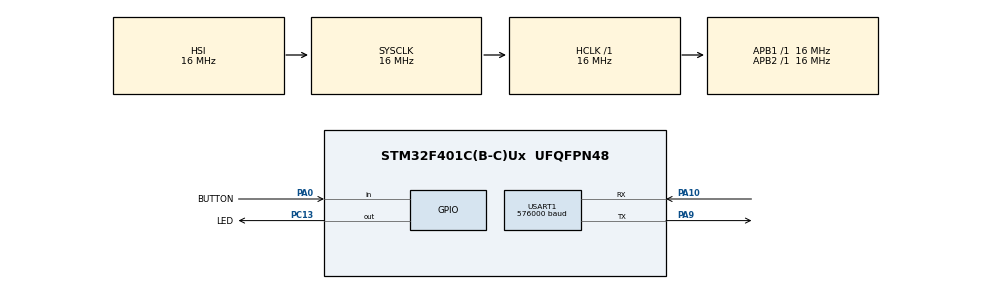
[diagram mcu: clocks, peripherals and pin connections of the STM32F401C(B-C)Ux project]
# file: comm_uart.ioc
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FREERTOS.Queues01=myQueue01,16,uint16_t,0,Static,myQueue01Buffer,myQueue01ControlBlock
FREERTOS.Tasks01=defaultTask,24,128,StartDefaultTask,Default,NULL,Dynamic,NULL,NULL
FREERTOS.configENABLE_FPU=1
FREERTOS.configUSE_NEWLIB_REENTRANT=1
Mcu.Family=STM32F4
Mcu.Name=STM32F401C(B-C)Ux
Mcu.Package=UFQFPN48
NVIC.PriorityGroup=NVIC_PRIORITYGROUP_4
NVIC.TIM5_IRQn=true\:15\:0\:false\:false\:true\:false\:false\:true\:true
NVIC.TimeBase=TIM5_IRQn
NVIC.TimeBaseIP=TIM5
NVIC.USART1_IRQn=true\:5\:0\:false\:false\:true\:true\:true\:true\:true
PA0-WKUP.GPIO_Label=BUTTON
PA0-WKUP.GPIO_PuPd=GPIO_PULLUP
PA0-WKUP.Signal=GPIO_Input
PA10.Mode=Asynchronous
PA10.Signal=USART1_RX
PA13.Mode=Serial_Wire
PA13.Signal=SYS_JTMS-SWDIO
PA14.Mode=Serial_Wire
PA14.Signal=SYS_JTCK-SWCLK
PA9.Mode=Asynchronous
PA9.Signal=USART1_TX
PC13-ANTI_TAMP.GPIO_Label=LED
PC13-ANTI_TAMP.Signal=GPIO_Output
PH0\ -\ OSC_IN.Mode=HSE-External-Oscillator
PH0\ -\ OSC_IN.Signal=RCC_OSC_IN
PH1\ -\ OSC_OUT.Mode=HSE-External-Oscillator
PH1\ -\ OSC_OUT.Signal=RCC_OSC_OUT
ProjectManager.HeapSize=0x200
ProjectManager.StackSize=0x400
ProjectManager.TargetToolchain=STM32CubeIDE
RCC.AHBFreq_Value=16000000
RCC.APB1Freq_Value=16000000
RCC.APB2Freq_Value=16000000
RCC.CortexFreq_Value=16000000
RCC.HSE_VALUE=25000000
RCC.HSI_VALUE=16000000
RCC.LSE_VALUE=32768
RCC.SYSCLKFreq_VALUE=16000000
RCC.VCOOutputFreq_Value=192000000
USART1.BaudRate=576000
USART1.Parity=PARITY_ODD
USART1.VirtualMode=VM_ASYNC
USART1.WordLength=WORDLENGTH_9B
VP_FREERTOS_VS_CMSIS_V2.Mode=CMSIS_V2
VP_SYS_VS_tim5.Mode=TIM5
board=custom

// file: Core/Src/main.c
/* USER CODE BEGIN Header */
/**
  ******************************************************************************
  * @file           : main.c
  * @brief          : Main program body
  ******************************************************************************
  * @attention
  *
  * Copyright (c) 2022 STMicroelectronics.
  * All rights reserved.
  *
  * This software is licensed under terms that can be found in the LICENSE file
  * in the root directory of this software component.
  * If no LICENSE file comes with this software, it is provided AS-IS.
  *
  ******************************************************************************
  */
/* USER CODE END Header */
#include "main.h"
#include "cmsis_os.h"

/* USER CODE BEGIN Includes */
#include <stdint.h>
#include "maincode.h"
/* USER CODE END Includes */

typedef StaticQueue_t osStaticMessageQDef_t;

 UART_HandleTypeDef huart1;

/* Definitions for defaultTask */
osThreadId_t defaultTaskHandle;
const osThreadAttr_t defaultTask_attributes = {
  .name = "defaultTask",
  .stack_size = 128 * 4,
  .priority = (osPriority_t) osPriorityNormal,
};
/* Definitions for myQueue01 */
osMessageQueueId_t myQueue01Handle;
uint8_t myQueue01Buffer[ 16 * sizeof( uint16_t ) ];
osStaticMessageQDef_t myQueue01ControlBlock;
const osMessageQueueAttr_t myQueue01_attributes = {
  .name = "myQueue01",
  .cb_mem = &myQueue01ControlBlock,
  .cb_size = sizeof(myQueue01ControlBlock),
  .mq_mem = &myQueue01Buffer,
  .mq_size = sizeof(myQueue01Buffer)
};

void SystemClock_Config(void);
static void MX_GPIO_Init(void);
static void MX_USART1_UART_Init(void);
void StartDefaultTask(void *argument);

int main(void)
{

  /* MCU Configuration--------------------------------------------------------*/

  /* Reset of all peripherals, Initializes the Flash interface and the Systick. */
  HAL_Init();

  /* Configure the system clock */
  SystemClock_Config();

  /* Initialize all configured peripherals */
  MX_GPIO_Init();
  MX_USART1_UART_Init();
  /* USER CODE BEGIN 2 */
  start_rtos();
  /* USER CODE END 2 */

  /* Init scheduler */
  osKernelInitialize();

  /* Create the queue(s) */
  /* creation of myQueue01 */
  myQueue01Handle = osMessageQueueNew (16, sizeof(uint16_t), &myQueue01_attributes);

  /* Create the thread(s) */
  /* creation of defaultTask */
  defaultTaskHandle = osThreadNew(StartDefaultTask, NULL, &defaultTask_attributes);

  /* Start scheduler */
  osKernelStart();

  /* We should never get here as control is now taken by the scheduler */
  /* Infinite loop */
  while (1)
  {

  }
}

void SystemClock_Config(void)
{
  RCC_OscInitTypeDef RCC_OscInitStruct = {0};
  RCC_ClkInitTypeDef RCC_ClkInitStruct = {0};

  /** Configure the main internal regulator output voltage
  */
  __HAL_RCC_PWR_CLK_ENABLE();
  __HAL_PWR_VOLTAGESCALING_CONFIG(PWR_REGULATOR_VOLTAGE_SCALE2);

  /** Initializes the RCC Oscillators according to the specified parameters
  * in the RCC_OscInitTypeDef structure.
  */
  RCC_OscInitStruct.OscillatorType = RCC_OSCILLATORTYPE_HSI;
  RCC_OscInitStruct.HSIState = RCC_HSI_ON;
  RCC_OscInitStruct.HSICalibrationValue = RCC_HSICALIBRATION_DEFAULT;
  RCC_OscInitStruct.PLL.PLLState = RCC_PLL_NONE;
  if (HAL_RCC_OscConfig(&RCC_OscInitStruct) != HAL_OK)
  {
    Error_Handler();
  }

  /** Initializes the CPU, AHB and APB buses clocks
  */
  RCC_ClkInitStruct.ClockType = RCC_CLOCKTYPE_HCLK|RCC_CLOCKTYPE_SYSCLK
                              |RCC_CLOCKTYPE_PCLK1|RCC_CLOCKTYPE_PCLK2;
  RCC_ClkInitStruct.SYSCLKSource = RCC_SYSCLKSOURCE_HSI;
  RCC_ClkInitStruct.AHBCLKDivider = RCC_SYSCLK_DIV1;
  RCC_ClkInitStruct.APB1CLKDivider = RCC_HCLK_DIV1;
  RCC_ClkInitStruct.APB2CLKDivider = RCC_HCLK_DIV1;

  if (HAL_RCC_ClockConfig(&RCC_ClkInitStruct, FLASH_LATENCY_0) != HAL_OK)
  {
    Error_Handler();
  }
}

static void MX_USART1_UART_Init(void)
{

  huart1.Instance = USART1;
  huart1.Init.BaudRate = 576000;
  huart1.Init.WordLength = UART_WORDLENGTH_9B;
  huart1.Init.StopBits = UART_STOPBITS_1;
  huart1.Init.Parity = UART_PARITY_ODD;
  huart1.Init.Mode = UART_MODE_TX_RX;
  huart1.Init.HwFlowCtl = UART_HWCONTROL_NONE;
  huart1.Init.OverSampling = UART_OVERSAMPLING_16;
  if (HAL_UART_Init(&huart1) != HAL_OK)
  {
    Error_Handler();
  }
  /* USER CODE BEGIN USART1_Init 2 */
  NVIC_SetPriority(USART1_IRQn, NVIC_EncodePriority(NVIC_GetPriorityGrouping(),0, 0));
  NVIC_EnableIRQ(USART1_IRQn);
  /* USER CODE END USART1_Init 2 */

}

static void MX_GPIO_Init(void)
{
  GPIO_InitTypeDef GPIO_InitStruct = {0};

  /* GPIO Ports Clock Enable */
  __HAL_RCC_GPIOC_CLK_ENABLE();
  __HAL_RCC_GPIOH_CLK_ENABLE();
  __HAL_RCC_GPIOA_CLK_ENABLE();

  /*Configure GPIO pin Output Level */
  HAL_GPIO_WritePin(LED_GPIO_Port, LED_Pin, GPIO_PIN_RESET);

  /*Configure GPIO pin : LED_Pin */
  GPIO_InitStruct.Pin = LED_Pin;
  GPIO_InitStruct.Mode = GPIO_MODE_OUTPUT_PP;
  GPIO_InitStruct.Pull = GPIO_NOPULL;
  GPIO_InitStruct.Speed = GPIO_SPEED_FREQ_LOW;
  HAL_GPIO_Init(LED_GPIO_Port, &GPIO_InitStruct);

  /*Configure GPIO pin : BUTTON_Pin */
  GPIO_InitStruct.Pin = BUTTON_Pin;
  GPIO_InitStruct.Mode = GPIO_MODE_INPUT;
  GPIO_InitStruct.Pull = GPIO_PULLUP;
  HAL_GPIO_Init(BUTTON_GPIO_Port, &GPIO_InitStruct);

}

void StartDefaultTask(void *argument)
{
  for(;;)
  {
    osDelay(1);
  }
}

void HAL_TIM_PeriodElapsedCallback(TIM_HandleTypeDef *htim)
{
  if (htim->Instance == TIM5) {
    HAL_IncTick();
  }
}

void Error_Handler(void)
{
  __disable_irq();
  while (1)
  {
  }
}
